# RL6842_IP_SVD register map
Vendor: Realtek
Registers are 32-bit, read-write, reset 0x0 unless marked. A register's access mark holds for its fields unless they carry their own. Offsets are from the block's base; [hi:lo] are bit positions; {n}, {i} and the like mark numbered series; <NAME> marks a mode.

## ADC_REG
Base 0x4101C000
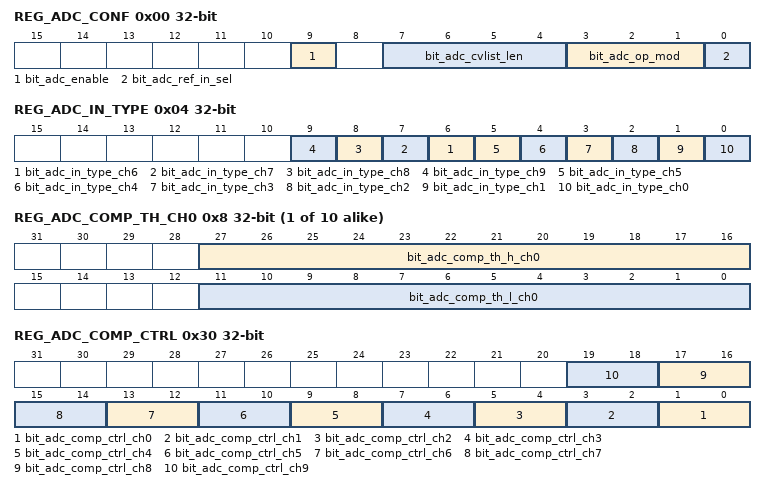
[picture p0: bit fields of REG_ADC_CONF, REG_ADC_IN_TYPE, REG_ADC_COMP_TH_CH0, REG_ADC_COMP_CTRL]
0x00 REG_ADC_CONF — ADC Configuration Register
  [9] bit_adc_enable — This bit is for ADC enable control
  [7:4] bit_adc_cvlist_len — This field defines the number of items in the ADC conversion channel list.
  [3:1] bit_adc_op_mod — These bits selects ADC operation mode. 0: software trigger mode 1: automatic mode 2: timer-trigger mode 3: comparator-assist mode
  [0] bit_adc_ref_in_sel — This bit selects ADC reference voltage input. 0: ADC's reference voltage is from internal source. 1: ADC's reference voltage is from external pin.
0x04 REG_ADC_IN_TYPE access per field — ADC Input Type Register
  [n] bit_adc_in_type_ch{n} ro (n=6..9) — This bit reflects which kind of input type channel {n} is. Since channel {n} is a fixed internal channel.
  [5] bit_adc_in_type_ch5 rw — This bit controls channel 5 input type. If it's set to differential type(value of this bit is 1), channel 4 should also be set to differential type since they are hardware-fixed differential pair. 0: ADC channel 5 is single-end input. 1: ADC channel 5 is differential input which is paired with channel 4.
  [4] bit_adc_in_type_ch4 rw — This bit controls channel 4 input type. If it's set to differential type(value of this bit is 1), channel 5 should also be set to differential type since they are hardware-fixed differential pair. 0: ADC channel 4 is single-end input. 1: ADC channel 4 is differential input which is paired with channel 5.
  [3] bit_adc_in_type_ch3 rw — This bit controls channel 3 input type. If it's set to differential type(value of this bit is 1), channel 2 should also be set to differential type since they are hardware-fixed differential pair. 0: ADC channel 3 is single-end input. 1: ADC channel 3 is differential input which is paired with channel 2.
  [2] bit_adc_in_type_ch2 rw — This bit controls channel 2 input type. If it's set to differential type(value of this bit is 1), channel 3 should also be set to differential type since they are hardware-fixed differential pair. 0: ADC channel 2 is single-end input. 1: ADC channel 2 is differential input which is paired with channel 3.
  [1] bit_adc_in_type_ch1 rw — This bit controls channel 1 input type. If it's set to differential type(value of this bit is 1), channel 0 should also be set to differential type since they are hardware-fixed differential pair. 0: ADC channel 1 is single-end input. 1: ADC channel 1 is differential input which is paired with channel 0.
  [0] bit_adc_in_type_ch0 rw — This bit controls channel 0 input type. If it's set to differential type(value of this bit is 1), channel 1 should also be set to differential type since they are hardware-fixed differential pair. 0: ADC channel 0 is single-end input. 1: ADC channel 0 is differential input which is paired with channel 1.
{0x8+4i} REG_ADC_COMP_TH_CH{i} (i=0..9) — ADC Channel {i} Comparison Threshold Register
  [27:16] bit_adc_comp_th_h_ch{i} — This field defines the higher threshold of channel {i} for ADC automatic comparison.
  [11:0] bit_adc_comp_th_l_ch{i} — This field defines the lower threshold of channel {i} for ADC automatic comparison.
0x30 REG_ADC_COMP_CTRL — ADC Comparison Control Register
  [2n+1:2n] bit_adc_comp_ctrl_ch{n} (n=0..9) — This field defines ADC channel comparison criteria which would notify system by interrupt when the criterion matches. Once a criterion matches, ADC should send an interrupt signal to system if the related interrupt mask is unmask. ADC also updates comparison results in reg_adc_comp_sts. 0: When Vin < bit_adc_comp_th_l_chx, comparison criterion matches. 1: When Vin > bit_adc_comp_th_h_chx, comparison criterion matches. 2: When Vin >= bit_adc_comp_th_l_chx and Vin <= bit_adc_comp_th_h_chx, comparison criterion matches. 3: When Vin < bit_adc_comp_th_l_chx or Vin > bit_adc_comp_th_h_chx, comparison criterion matches.
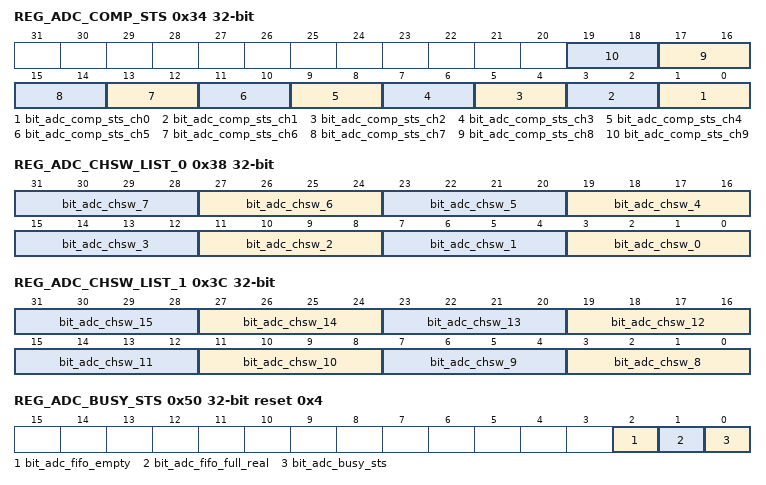
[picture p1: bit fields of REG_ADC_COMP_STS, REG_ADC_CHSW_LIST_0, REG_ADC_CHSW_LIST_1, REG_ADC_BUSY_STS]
0x34 REG_ADC_COMP_STS ro — ADC Comparison Status Register
  [2n+1:2n] bit_adc_comp_sts_ch{n} (n=0..9) — This field reflects the comparison result of channel {n} immediately.
0x38 REG_ADC_CHSW_LIST_0 — ADC Channel Switch List 0 Register
  [4n+3:4n] bit_adc_chsw_{n} (n=0..7) — This field defines the number {n} channel to do a conversion when a conversion event takes place.
0x3C REG_ADC_CHSW_LIST_1 — ADC Channel Switch List 1 Register
  [4n-29:4n-32] bit_adc_chsw_{n} (n=8..15) — This field defines the number {n} channel to do a conversion when a conversion event takes place.
0x40 REG_ADC_RST_LIST — ADC Reset Channel List Register
  [0] bit_adc_rst_list — This bit controls to reset the channel switch to default state or not. Once this bit is set, the auto/manual channel switch goes to the first channel as a default state. 0: Do Not reset conversion list to default state. 1: Reset conversion list to default state.
0x44 REG_ADC_AUTO_CSW_CTRL — ADC Automatic Channel Switch Control Register
  [0] bit_adc_auto_csw_en — This bit controls the automatic channel switch enabled or disabled. 0: Disable the automatic channel switch.If an automatic channel switch is in process, writing 0 will terminate the automatic channel switch. 1: Enable the automatic channel switch. When setting this bit, an automatic channel switch starts from the first channel in the channel switch list.
0x48 REG_ADC_SW_TRIG — ADC Software Trigger Register
  [0] bit_adc_sw_trig — This bit controls the ADC module to do a conversion. Every time this bit is set to 1, ADC module would switch to a new channel and do one conversion. Therefore, this bit could be used as a start-convert event which is controlled by software. Every time a conversion is done, software MUST clear this bit manually. 0: disable the analog module and analog mux. 1: enable the analog module and analog mux. And then start a new channel conversion.
0x4C REG_ADC_LAST_CH ro — ADC Last Channel Register
  [3:0] bit_adc_last_ch — This field reflects the last used channel
0x50 REG_ADC_BUSY_STS ro reset 0x4 — ADC Busy Status Register
  [2] bit_adc_fifo_empty — 0: FIFO in ADC not empty 1: FIFO in ADC empty
  [1] bit_adc_fifo_full_real — 0: FIFO in ADC not full real 1: FIFO in ADC full real
  [0] bit_adc_busy_sts — This bit reflects the ADC is busy or not. If the ADC is processing a conversion of a channel, this bit remains 1 which indicates it's busy. Once a conversion is done, this bit becomes 0 which indicates it's ready to do another conversion. 0: The ADC is ready. 1: The ADC is busy.
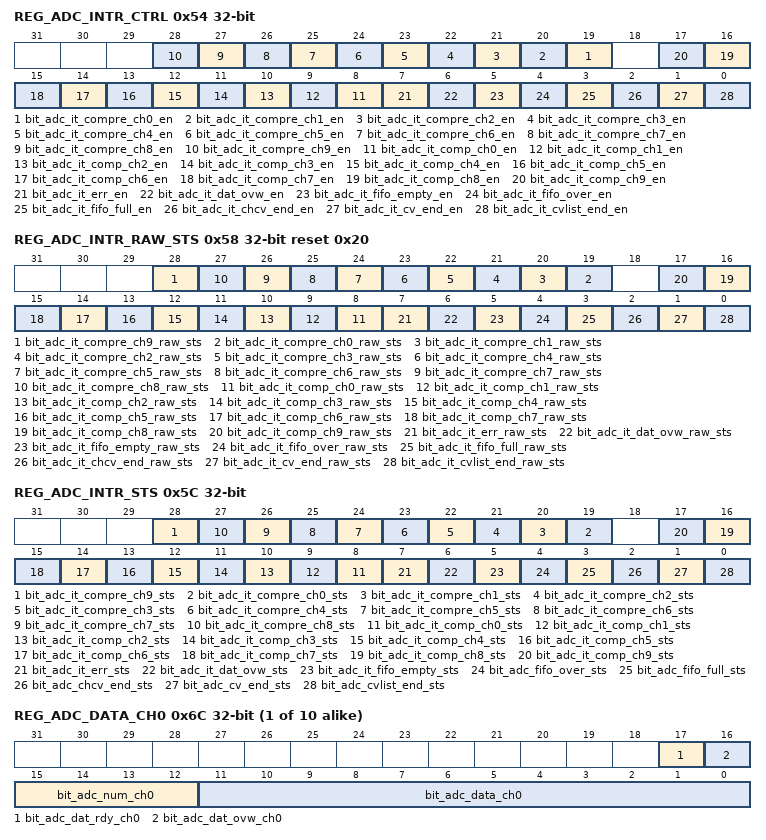
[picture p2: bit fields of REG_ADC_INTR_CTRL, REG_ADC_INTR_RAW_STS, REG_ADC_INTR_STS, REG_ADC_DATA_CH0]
0x54 REG_ADC_INTR_CTRL — ADC Interrupt Control Register
  [n+19] bit_adc_it_compre_ch{n}_en (n=0..9) — This bit controls the interrupt is enabled or not when channel {n} comparison criterion matching is rising edge. 0: This interrupt is disabled. 1: This interrupt is enabled.
  [n+8] bit_adc_it_comp_ch{n}_en (n=0..9) — This bit controls the interrupt is enabled or not when channel {n} comparison criterion matches. 0: This interrupt is disabled. 1: This interrupt is enabled.
  [7] bit_adc_it_err_en — This bit controls the interrupt is enabled or not when an error state takes place. 0: This interrupt is disabled. 1: This interrupt is enabled.
  [6] bit_adc_it_dat_ovw_en — This bit controls the interrupt is enabled or not when a data overwritten situation takes place. 0: This interrupt is disabled. 1: This interrupt is enabled.
  [5] bit_adc_it_fifo_empty_en — This bit controls the interrupt is enabled or not when a FIFO empty state takes place. 0: This interrupt is disabled. 1: This interrupt is enabled.
  [4] bit_adc_it_fifo_over_en — This bit controls the interrupt is enabled or not when a FIFO overflow state takes place. 0: This interrupt is disabled. 1: This interrupt is enabled.
  [3] bit_adc_it_fifo_full_en — This bit controls the interrupt is enabled or not when a FIFO full state takes place. 0: This interrupt is disabled. 1: This interrupt is enabled.
  [2] bit_adc_it_chcv_end_en — This bit controls the interrupt is enabled or not when a particular channel conversion is done. Please refer to reg_adc_it_chno_con 0: This interrupt is disabled. 1: This interrupt is enabled.
  [1] bit_adc_it_cv_end_en — This bit controls the interrupt is enabled or not every time a conversion is done. No matter ADC module is in what kind of operation mode. Every time a conversion is executed, ADC module would notify system if This bit is set. 0: This interrupt is disabled. 1: This interrupt is enabled.
  [0] bit_adc_it_cvlist_end_en — This bit controls the interrupt is enabled or not when a conversion of the last channel in the list is done. For example, in automatic mode conversions would be executed continuously. Every time the last channel conversion is done, which means all channel conversions in the list is done, ADC could notify system if This bit is set. 0: This interrupt is disabled. 1: This interrupt is enabled.
0x58 REG_ADC_INTR_RAW_STS ro reset 0x20 — ADC Interrupt Raw Status Register
  [28] bit_adc_it_compre_ch9_raw_sts
  [n+19] bit_adc_it_compre_ch{n}_raw_sts (n=0..8) — merged
  [n+8] bit_adc_it_comp_ch{n}_raw_sts (n=0..9) — merged
  [7] bit_adc_it_err_raw_sts — merged
  [6] bit_adc_it_dat_ovw_raw_sts — merged
  [5] bit_adc_it_fifo_empty_raw_sts — merged
  [4] bit_adc_it_fifo_over_raw_sts — merged
  [3] bit_adc_it_fifo_full_raw_sts — merged
  [2] bit_adc_it_chcv_end_raw_sts — merged
  [1] bit_adc_it_cv_end_raw_sts — merged
  [0] bit_adc_it_cvlist_end_raw_sts — merged
0x5C REG_ADC_INTR_STS ro — ADC Interrupt Status Register
  [28] bit_adc_it_compre_ch9_sts
  [n+19] bit_adc_it_compre_ch{n}_sts (n=0..8) — merged
  [n+8] bit_adc_it_comp_ch{n}_sts (n=0..9) — merged
  [7] bit_adc_it_err_sts — merged
  [6] bit_adc_it_dat_ovw_sts — merged
  [5] bit_adc_it_fifo_empty_sts — merged
  [4] bit_adc_fifo_over_sts — merged
  [3] bit_adc_fifo_full_sts — merged
  [2] bit_adc_chcv_end_sts — merged
  [1] bit_adc_cv_end_sts — merged
  [0] bit_adc_cvlist_end_sts — merged
0x60 REG_ADC_IT_CHNO_CON — ADC Interrupt Channel Number Configuration Register
  [3:0] bit_adc_it_chno_con — This field defines that ADC module should send interrupt signal to system when a conversion which of channel number is the same as this field. This register is only valid when bit_adc_it_chcv_end_en is set. bit_adc_it_chno_con: channel number
0x64 REG_ADC_FULL_LVL — ADC FIFO Full Threshold Register
  [5:0] bit_adc_full_lvl — This field defines the FIFO full entry thredshold level and it's used for FIFO full interrupt. It should be set according to ADC FIFO depth. A value of 0 sets the threshold for 1 entry, and a value of 15 sets the threshold for 16 entries.
0x68 REG_ADC_EXT_TRIG_TIMER_SEL — ADC External Trigger Timer Select Register
  [2:0] bit_adc_ext_trig_timer_sel — These three bits defines which timer channel would be used to make ADC module do a conversion. 0: Timer module 0 is used as the comparator external trigger source. 1: Timer module 1 is used as the comparator external trigger source. .. 7: Timer module 7 is used as the comparator external trigger source.
{0x6C+4i} REG_ADC_DATA_CH{i} ro (i=0..9) — ADC Channel {i} Data Register
  [17] bit_adc_dat_rdy_ch{i} — This bit indicates that a conversion is done. Every time a conversion is done, this bit should be set to 1 and it would be cleared to 0 when a read operation of reg_adc_data_ch{i}.
  [16] bit_adc_dat_ovw_ch{i} — This bit indicates that there is a data overwritten situation in bit_adc_data_ch{i} taking place. A data overwritten situation is that a former conversion data is NOT read before a new conversion is written to data field. It would be cleared to 0 when a read operation of reg_adc_data_ch{i}. 0: There is no data overwritten case. 1: There is a data overwritten case.
  [15:12] bit_adc_num_ch{i} — This field contains the newest conversion data of channel {i} [15:12]: which channel in channel list the data belongs to, only valid when bit_adc_ch_unmask=1
  [11:0] bit_adc_data_ch{i} — This field contains the newest conversion data of channel {i} [11:0]: newest data
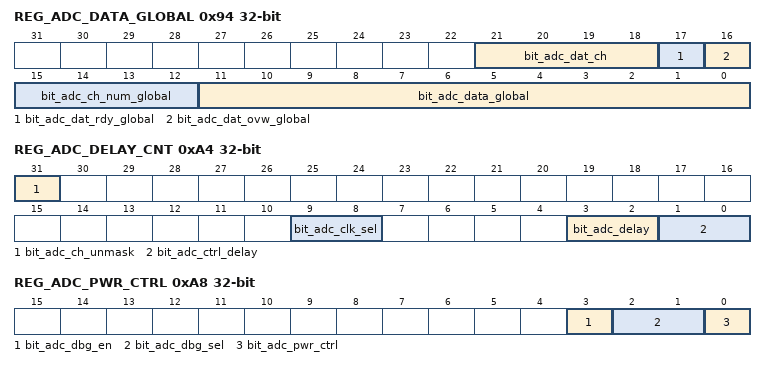
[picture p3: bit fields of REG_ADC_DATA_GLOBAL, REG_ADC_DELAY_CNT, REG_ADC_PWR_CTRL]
0x94 REG_ADC_DATA_GLOBAL ro — ADC Global Data Register
  [21:18] bit_adc_dat_ch — This field indicates which channel data is procedd right now
  [17] bit_adc_dat_rdy_global — This bit indicates that a conversion is done. Every time a conversion is done, this bit should be set to 1 and it would be cleared to 0 when a read operation of reg_adc_data_global
  [16] bit_adc_dat_ovw_global — This bit indicates that there is a data overwritten situation in bit_adc_data_global taking place. A data overwritten situation is that a former conversion data is NOT read before a new conversion is written to data field. 0: there is no data overwritten case. 1: there is a data overwritten case.
  [15:12] bit_adc_ch_num_global — This field contains the newest conversion data of channel in the list. [15:12]: which channel in channel list the data belongs to, only valid when bit_adc_ch_unmask=1
  [11:0] bit_adc_data_global — This field contains the newest conversion data of channel in the list. [11:0]: newest data
0x98 REG_ADC_FLR ro — ADC FIFO Level Register
  [4:0] bit_adc_flr — This field records the current ADC FIFO entry number.
0x9C REG_ADC_CLR_FIFO — ADC Clear FIFO Register
  [0] bit_adc_clr_fifo — This bit is used to clear FIFO contents and makes it to the default status. Every time this bit is set to 1. FIFO would be cleared to the default status. Software should set this bit to 0 after FIFO is cleared. 0: No effect 1: Clear FIFO
0xA0 REG_ADC_CLK_DIV reset 0x3 — ADC Clock Divider Register
  [2:0] bit_adc_clk_div — This field defines clock driver level of ADC module. A value of 0 is for clock divided by 2. A value of 1 is for clock divided by 4. A value of 2 is for clock divided by 8. A value of 3 is for clock divided by 12. A value of 4 is for clock divided by 16. A value of 5 is for clock divided by 32. A value of 6 is for clock divided by 64.
0xA4 REG_ADC_DELAY_CNT — ADC Delay Count Register
  [31] bit_adc_ch_unmask — Enable BIT_ADC_DAT_CHID
  [9:8] bit_adc_clk_sel — Just config to 00
  [3:2] bit_adc_delay — This field defines channel switch data delay count. A value of 0 is for using default count of hardware.
  [1:0] bit_adc_ctrl_delay — This field defines channel switch ctrl delay count. A value of 0 is for using default count of hardware.
0xA8 REG_ADC_PWR_CTRL — ADC Power Control Register
  [3] bit_adc_dbg_en — Debug port enable
  [2:1] bit_adc_dbg_sel — Debug port select
  [0] bit_adc_pwr_ctrl — This field is used to power control
0xAC REG_ADC_SW_TMODE — ADC Software Test Mode
  [0] bit_adc_sw_tmode — This bit is used to change the high 4 bits in FIFO. 0: normal mode, the high 4 bits will be null or the channel number 1: software test mode, the high 4 bits will be the counter number of sample points. (loop from 0 to 15)
0xB0 REG_ADC_DUMMY reset 0xFFFF — ADC Dummy Register
